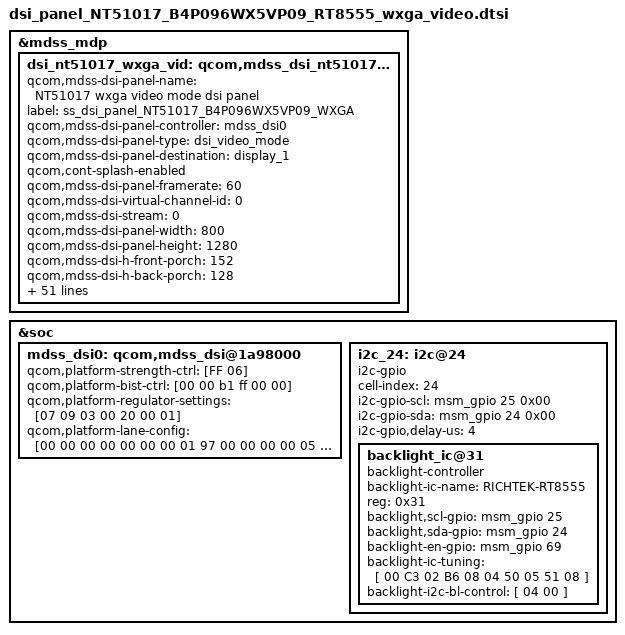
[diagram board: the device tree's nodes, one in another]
/* Copyright (c) 2013, The Linux Foundation. All rights reserved.
 *
 * This program is free software; you can redistribute it and/or modify
 * it under the terms of the GNU General Public License version 2 and
 * only version 2 as published by the Free Software Foundation.
 *
 * This program is distributed in the hope that it will be useful,
 * but WITHOUT ANY WARRANTY; without even the implied warranty of
 * MERCHANTABILITY or FITNESS FOR A PARTICULAR PURPOSE.  See the
 * GNU General Public License for more details.
 */

/*---------------------------------------------------------------------------
 * This file is autogenerated file using gcdb parser. Please do not edit it.
 * Update input XML file to add a new entry or update variable in this file
 * VERSION = "1.0"
 *---------------------------------------------------------------------------*/
&mdss_mdp {
	dsi_nt51017_wxga_vid: qcom,mdss_dsi_nt51017_wxga_video {
		qcom,mdss-dsi-panel-name = "NT51017 wxga video mode dsi panel";
		label = "ss_dsi_panel_NT51017_B4P096WX5VP09_WXGA";
		qcom,mdss-dsi-panel-controller = <&mdss_dsi0>;
		qcom,mdss-dsi-panel-type = "dsi_video_mode";
		qcom,mdss-dsi-panel-destination = "display_1";
		qcom,cont-splash-enabled;
		qcom,mdss-dsi-panel-framerate = <60>;
		qcom,mdss-dsi-virtual-channel-id = <0>;
		qcom,mdss-dsi-stream = <0>;
		qcom,mdss-dsi-panel-width = <800>;
		qcom,mdss-dsi-panel-height = <1280>;
		qcom,mdss-dsi-h-front-porch = <152>;
		qcom,mdss-dsi-h-back-porch = <128>;
		qcom,mdss-dsi-h-pulse-width = <8>;
		qcom,mdss-dsi-h-sync-skew = <0>;
		qcom,mdss-dsi-v-back-porch = <23>;
		qcom,mdss-dsi-v-front-porch = <18>;
		qcom,mdss-dsi-v-pulse-width = <1>;
		qcom,mdss-dsi-h-left-border = <0>;
		qcom,mdss-dsi-h-right-border = <0>;
		qcom,mdss-dsi-v-top-border = <0>;
		qcom,mdss-dsi-v-bottom-border = <0>;
		qcom,mdss-dsi-bpp = <24>;
		qcom,mdss-dsi-underflow-color = <0xff>;
		qcom,mdss-dsi-border-color = <0>;
		qcom,mdss-dsi-on-command-state = "dsi_hs_mode";
		qcom,mdss-dsi-off-command-state = "dsi_hs_mode";
		qcom,mdss-dsi-h-sync-pulse = <0>;
		qcom,mdss-dsi-bllp-eof-power-mode;
		qcom,mdss-dsi-bllp-power-mode;
		qcom,mdss-dsi-lane-0-state;
		qcom,mdss-dsi-lane-1-state;
		qcom,mdss-dsi-lane-2-state;
		qcom,mdss-dsi-lane-3-state;
		qcom,mdss-dsi-panel-timings = [94 20 14 00 46 4a 1a 24 18 03 04 00];
		qcom,mdss-dsi-t-clk-post = <0x04>;
		qcom,mdss-dsi-t-clk-pre = <0x1D>;
		qcom,mdss-dsi-bl-min-level = <1>;
		qcom,mdss-dsi-bl-max-level = <255>;
		qcom,mdss-dsi-dma-trigger = "trigger_sw";
		qcom,mdss-dsi-mdp-trigger = "none";
		qcom,mdss-dsi-bl-pmic-control-type = "bl_ctrl_ss_pwm";
		qcom,mdss-dsi-on-command = [
			39 01 00 00 00 00 02 83 96
			39 01 00 00 00 00 02 84 69
			39 01 00 00 00 00 02 92 19
			39 01 00 00 00 00 02 95 00
			39 01 00 00 00 00 02 83 00
			39 01 00 00 00 00 02 84 00
			39 01 00 00 00 00 02 90 77
			39 01 00 00 00 00 02 94 FF
			39 01 00 00 00 00 02 96 FF
			39 01 00 00 00 00 02 91 FD
			39 01 00 00 00 00 02 90 77
		];
		
		samsung,cabc_on_tx_cmds_revA = [
			39 01 00 00 00 00 02 96 3F
		];
		samsung,cabc_off_tx_cmds_revA = [
			39 01 00 00 00 00 02 96 FF
		];
		/*
		* ************************************************************************************************************************
		* Scaled level to index mappings
		* ************************************************************************************************************************
		*/
		samsung,scaled_level_map_table_revA = <
		/*<idx>	  <from>  <till> <scaled_level> */
			0		0		0		0
			1		1		10		3 /* min */
			2		11		12		10 
			3		13		14		15
			4		15		17		20
			5		18		19		25
			6		20		22		30
			7		23		24		36
			8		25		27		38
			9		28		29		39
			10		30		32		40
			11		33		34		41
			12		35		37		43
			13		38		39		44
			14		40		42		45
			15		43		44		46
			16		45		47		48
			17		48		49		49
			18		50		52		50
			19		53		54		51
			20		55		57		52
			21		58		59		54
			22		60		62		56
			23		63		64		58
			24		65		67		60
			25		68		70		62
			26		71		72		64
			27		73		75		66
			28		76		77		68
			29		78		80		70
			30		81		82		72
			31		83		85		74
			32		86		87		76
			33		88		90		78
			34		91		92		80
			35		93		95		82
			36		96		97		84
			37		98		100		86
			38		101		102		88
			39		103		105		90
			40		106		107		92
			41		108		110		94
			42		111		112		96
			43		113		115		98
			44		116		117		100
			45		118		120		102
			46		121		122		104
			47		123		125		106
			48		126		127		108
			49		128		130		110
			50		131		133		112
			51		134		135		114
			52		136		138		116
			53		139		140		118
			54		141		143		120  /* default */
			55		144		145		122
			56		146		148		125
			57		149		150		129
			58		151		153		132
			59		154		155		135
			60		156		158		137
			61		159		160		139
			62		161		163		142
			63		164		165		146
			64		166		168		150
			65		169		170		153
			66		171		173		156
			67		174		175		159
			68		176		178		162
			69		179		180		165
			70		181		183		169
			71		184		185		172
			72		186		188		176
			72		189		190		178
			74		191		193		181
			75		194		196		184
			76		197		198		188
			77		199		201		192
			78		202		203		196
			79		204		206		200
			80		207		208		203
			81		209		211		206
			82		212		213		210
			83		214		216		213
			84		217		218		216
			85		219		221		219
			86		222		223		223
			87		224		226		226
			88		227		228		229
			89		229		231		232
			90		232		233		236
			91		234		236		238
			92		237		238		240
			93		239		241		242
			94		242		243		244
			95		244		246		246
			96		247		248		248
			97		249		251		250
			98		252		253		252
			99		254		255		255 /* max */
		>;
		samsung,tft-common-support;
		samsung,panel-vendor = "BOE";
		samsung,tft-module-name = "TV096WXM";
		samsung,blic-discharging-delay-us = <100000>;
		samsung,mdss-power-on-reset-delay-us = <30000>;
		qcom,mdss-pan-physical-width-dimension = <129>;
		qcom,mdss-pan-physical-height-dimension = <206>;
		qcom,mdss-dsi-force-clk-lane-hs;

		qcom,mdss-dsi-hfp-power-mode;
		qcom,mdss-dsi-hbp-power-mode;
		qcom,mdss-dsi-hsa-power-mode;
		qcom,mdss-dsi-traffic-mode = "burst_mode";
	};
};

&soc {
	mdss_dsi0: qcom,mdss_dsi@1a98000 {
		qcom,platform-strength-ctrl = [FF 06];
		qcom,platform-bist-ctrl = [00 00 b1 ff 00 00];
		qcom,platform-regulator-settings = [07 09 03 00 20 00 01];
		qcom,platform-lane-config = [00 00 00 00 00 00 00 01 97
			00 00 00 00 05 00 00 01 97
			00 00 00 00 0a 00 00 01 97
			00 00 00 00 0f 00 00 01 97
			00 c0 00 00 00 00 00 01 bb];
		};
	
	i2c_24: i2c@24 {

		cell-index = <24>;
		compatible = "i2c-gpio";
		i2c-gpio-scl = <&msm_gpio 25  0x00>; /*scl gpio*/
		i2c-gpio-sda = <&msm_gpio 24 0x00>;  /*sda gpio*/
		i2c-gpio,delay-us = <4>;
		backlight_ic@31 {
			compatible = "backlight-controller";
			backlight-ic-name = "RICHTEK-RT8555";
			reg = <0x31>;
			backlight,scl-gpio = <&msm_gpio 25 0x00>;
			backlight,sda-gpio = <&msm_gpio 24 0x00>;
			backlight-en-gpio = <&msm_gpio 69 0x00>;
			backlight-ic-tuning = [
					00	C3
					02	B6
					08   04
					50   05
					51   08
			];
			backlight-i2c-bl-control = [
					04	00
			];

		};
	};
};
